# AT90USB1286 register map
Vendor: Atmel; File version: 1.0
CPU: other r0p0, little endian, no MPU, no FPU, 4 interrupt priority bits
Registers are 8-bit, read-write, reset 0x0 unless marked. A register's access mark holds for its fields unless they carry their own. Offsets are from the block's base; [hi:lo] are bit positions; {n}, {i} and the like mark numbered series; 'fields as' and 'values as' point back to an identical list.

## EEPROM
Base 0x0080003F
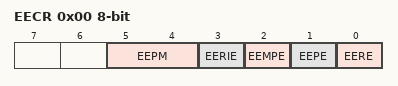
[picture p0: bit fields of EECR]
0x00 EECR — EEPROM Control Register
  [5:4] EEPM — EEPROM Programming Mode Bits
    0=ERASE_AND_WRITE_IN_ONE_OPERATION; 1=ERASE_ONLY; 2=WRITE_ONLY
  [3] EERIE — EEPROM Ready Interrupt Enable
  [2] EEMPE — EEPROM Master Write Enable
  [1] EEPE — EEPROM Write Enable
  [0] EERE — EEPROM Read Enable
0x01 EEDR — EEPROM Data Register
0x02 EEAR 16-bit (reset mask 0xFF) — EEPROM Address Register Low Bytes

## EXINT — External Interrupts
Base 0x0080003B
0x00 PCIFR — Pin Change Interrupt Flag Register (read-only for debugger)
  [0] PCIF0 — Pin Change Interrupt Flag 0
0x01 EIFR — External Interrupt Flag Register (read-only for debugger)
  [7:0] INTF — External Interrupt Flags
0x02 EIMSK — External Interrupt Mask Register
  [7:0] INT — External Interrupt Request 7 Enable
0x2D PCICR — Pin Change Interrupt Control Register
  [0] PCIE0 — Pin Change Interrupt Enable 0
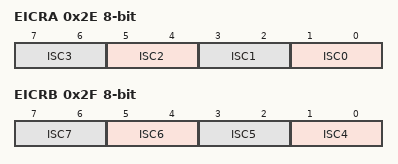
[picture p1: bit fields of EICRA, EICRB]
0x2E EICRA — External Interrupt Control Register A
  [all] fields
    0=LOW_LEVEL_OF_INTX; 1=ANY_LOGICAL_CHANGE_OF_INTX; 2=FALLING_EDGE_OF_INTX; 3=RISING_EDGE_OF_INTX
  [2n+1:2n] ISC{n} (n=0..3) — External Interrupt Sense Control Bit
0x2F EICRB — External Interrupt Control Register B
  [all] fields
    values as the fields of EICRA
  [2n-7:2n-8] ISC{n} (n=4..7) — External Interrupt 7-4 Sense Control Bit
0x30 PCMSK0 — Pin Change Mask Register 0

## JTAG — JTAG Interface
Base 0x00800051
0x00 OCDR — On-Chip Debug Related Register in I/O Memory (write-only for debugger)
0x03 MCUSR — MCU Status Register (read-only for debugger)
  [4] JTRF — JTAG Reset Flag
0x04 MCUCR — MCU Control Register
  [7] JTD — JTAG Interface Disable

## LOCKBIT — Lockbits
Base 0x00800000
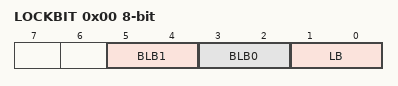
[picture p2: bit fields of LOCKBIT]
0x00 LOCKBIT
  [5:4] BLB1 — Boot Loader Protection Mode
    0=LPM_SPM_DISABLE (LPM and SPM prohibited in Boot Section); 1=LPM_DISABLE (LPM prohibited in Boot Section); 2=SPM_DISABLE (SPM prohibited in Boot Section); 3=NO_LOCK (No lock on SPM and LPM in Boot Section)
  [3:2] BLB0 — Boot Loader Protection Mode
    0=LPM_SPM_DISABLE (LPM and SPM prohibited in Application Section); 1=LPM_DISABLE (LPM prohibited in Application Section); 2=SPM_DISABLE (SPM prohibited in Application Section); 3=NO_LOCK (No lock on SPM and LPM in Application Section)
  [1:0] LB — Memory Lock
    0=PROG_VER_DISABLED (Further programming and verification disabled); 2=PROG_DISABLED (Further programming disabled); 3=NO_LOCK (No memory lock features enabled)

## PLL — Phase Locked Loop
Base 0x00800049
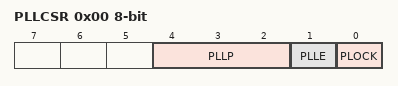
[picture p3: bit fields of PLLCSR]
0x00 PLLCSR — PLL Status and Control register
  [4:2] PLLP — PLL prescaler Bits
    3=CLOCK_4; 5=CLOCK_8
  [1] PLLE — PLL Enable Bit
  [0] PLOCK — PLL Lock Status Bit

## PORTA — I/O Port
Base 0x00800020
0x00 PINA — Port A Input Pins (read-only for debugger)
0x01 DDRA — Port A Data Direction Register
0x02 PORTA — Port A Data Register

## PORTB — I/O Port
Base 0x00800023
0x00 PINB — Port B Input Pins (read-only for debugger)
0x01 DDRB — Port B Data Direction Register
0x02 PORTB — Port B Data Register

## PORTC — I/O Port
Base 0x00800026
0x00 PINC — Port C Input Pins (read-only for debugger)
0x01 DDRC — Port C Data Direction Register
0x02 PORTC — Port C Data Register

## PORTD — I/O Port
Base 0x00800029
0x00 PIND — Port D Input Pins (read-only for debugger)
0x01 DDRD — Port D Data Direction Register
0x02 PORTD — Port D Data Register

## PORTE — I/O Port
Base 0x0080002C
0x00 PINE — Input Pins, Port E (read-only for debugger)
0x01 DDRE — Data Direction Register, Port E
0x02 PORTE — Data Register, Port E
